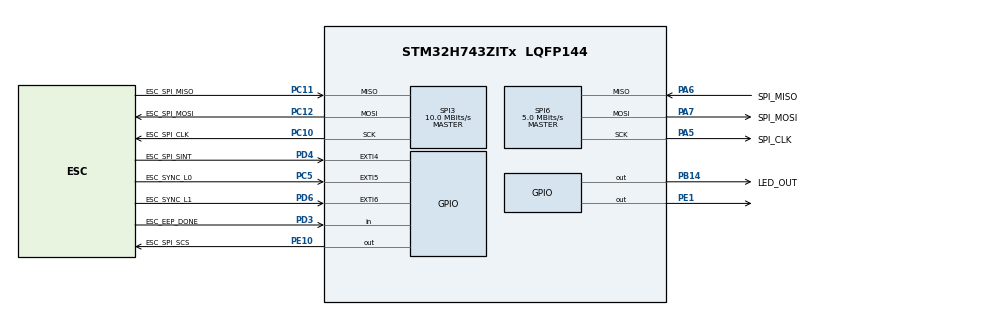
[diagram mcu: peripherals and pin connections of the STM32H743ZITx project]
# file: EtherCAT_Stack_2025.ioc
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CORTEX_M7.default_mode_Activation=1
Mcu.Family=STM32H7
Mcu.Name=STM32H743ZITx
Mcu.Package=LQFP144
NVIC.EXTI9_5_IRQn=true\:0\:0\:false\:false\:true\:true\:true\:true
NVIC.PriorityGroup=NVIC_PRIORITYGROUP_4
NVIC.SPI6_IRQn=true\:0\:0\:false\:false\:true\:true\:true\:true
NVIC.TIM7_IRQn=true\:0\:0\:false\:false\:true\:true\:true\:true
PA5.GPIO_Label=SPI_CLK
PA5.GPIO_Speed=GPIO_SPEED_FREQ_HIGH
PA5.Mode=Full_Duplex_Master
PA5.Signal=SPI6_SCK
PA6.GPIO_Label=SPI_MISO
PA6.GPIO_Speed=GPIO_SPEED_FREQ_VERY_HIGH
PA6.Mode=Full_Duplex_Master
PA6.Signal=SPI6_MISO
PA7.GPIO_Label=SPI_MOSI
PA7.GPIO_Speed=GPIO_SPEED_FREQ_HIGH
PA7.Mode=Full_Duplex_Master
PA7.Signal=SPI6_MOSI
PB14.GPIO_Label=LED_OUT
PB14.Signal=GPIO_Output
PC10.GPIO_Label=ESC_SPI_CLK
PC10.GPIO_PuPd=GPIO_PULLUP
PC10.GPIO_Speed=GPIO_SPEED_FREQ_HIGH
PC10.Mode=Full_Duplex_Master
PC10.Signal=SPI3_SCK
PC11.GPIO_Label=ESC_SPI_MISO
PC11.GPIO_Speed=GPIO_SPEED_FREQ_HIGH
PC11.Mode=Full_Duplex_Master
PC11.Signal=SPI3_MISO
PC12.GPIO_Label=ESC_SPI_MOSI
PC12.GPIO_PuPd=GPIO_PULLUP
PC12.GPIO_Speed=GPIO_SPEED_FREQ_HIGH
PC12.Mode=Full_Duplex_Master
PC12.Signal=SPI3_MOSI
PC5.GPIO_Label=ESC_SYNC_L0
PC5.GPIO_ModeDefaultEXTI=GPIO_MODE_IT_FALLING
PC5.GPIO_PuPd=GPIO_PULLUP
PC5.Signal=GPXTI5
PD3.GPIO_Label=ESC_EEP_DONE
PD3.GPIO_PuPd=GPIO_PULLDOWN
PD3.Signal=GPIO_Input
PD4.GPIO_Label=ESC_SPI_SINT
PD4.GPIO_ModeDefaultEXTI=GPIO_MODE_IT_FALLING
PD4.GPIO_PuPd=GPIO_PULLUP
PD4.Signal=GPXTI4
PD6.GPIO_Label=ESC_SYNC_L1
PD6.GPIO_ModeDefaultEXTI=GPIO_MODE_IT_FALLING
PD6.Signal=GPXTI6
PE1.Signal=GPIO_Output
PE10.GPIO_Label=ESC_SPI_SCS
PE10.GPIO_PuPd=GPIO_PULLUP
PE10.GPIO_Speed=GPIO_SPEED_FREQ_HIGH
PE10.PinState=GPIO_PIN_SET
PE10.Signal=GPIO_Output
ProjectManager.HeapSize=0x200
ProjectManager.StackSize=0x400
ProjectManager.TargetToolchain=STM32CubeIDE
RCC.ADCFreq_Value=129000000
RCC.APB1Freq_Value=80000000
RCC.APB2Freq_Value=80000000
RCC.APB3Freq_Value=80000000
RCC.APB4Freq_Value=40000000
RCC.CortexFreq_Value=80000000
RCC.D3PPRE=RCC_APB4_DIV2
RCC.DIVM1=4
RCC.DIVN1=10
RCC.HCLKFreq_Value=80000000
RCC.PLL2FRACN=0
RCC.PLL3FRACN=0
RCC.PLLFRACN=0
RCC.SYSCLKFreq_VALUE=80000000
RCC.SYSCLKSource=RCC_SYSCLKSOURCE_PLLCLK
RCC.USBFreq_Value=80000000
SPI3.BaudRatePrescaler=SPI_BAUDRATEPRESCALER_8
SPI3.CLKPhase=SPI_PHASE_2EDGE
SPI3.CLKPolarity=SPI_POLARITY_HIGH
SPI3.CalculateBaudRate=10.0 MBits/s
SPI3.DataSize=SPI_DATASIZE_8BIT
SPI3.Direction=SPI_DIRECTION_2LINES
SPI3.FifoThreshold=SPI_FIFO_THRESHOLD_04DATA
SPI3.Mode=SPI_MODE_MASTER
SPI3.VirtualType=VM_MASTER
SPI6.BaudRatePrescaler=SPI_BAUDRATEPRESCALER_8
SPI6.CLKPhase=SPI_PHASE_2EDGE
SPI6.CalculateBaudRate=5.0 MBits/s
SPI6.DataSize=SPI_DATASIZE_8BIT
SPI6.Direction=SPI_DIRECTION_2LINES
SPI6.Mode=SPI_MODE_MASTER
SPI6.VirtualType=VM_MASTER
TIM6.Period=999
TIM6.Prescaler=119
TIM7.Period=9999
TIM7.Prescaler=239
VP_MEMORYMAP_VS_MEMORYMAP.Mode=CurAppReg
VP_TIM6_VS_ClockSourceINT.Mode=Enable_Timer
VP_TIM7_VS_ClockSourceINT.Mode=Enable_Timer
board=custom

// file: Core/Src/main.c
/* USER CODE BEGIN Header */
/**
  ******************************************************************************
  * @file           : main.c
  * @brief          : Main program body
  ******************************************************************************
  * @attention
  *
  * Copyright (c) 2025 STMicroelectronics.
  * All rights reserved.
  *
  * This software is licensed under terms that can be found in the LICENSE file
  * in the root directory of this software component.
  * If no LICENSE file comes with this software, it is provided AS-IS.
  *
  ******************************************************************************
  */
/* USER CODE END Header */
#include "main.h"
#include "spi.h"
#include "tim.h"
#include "gpio.h"

void SystemClock_Config(void);
static void MPU_Config(void);

int main(void)
{

  /* MPU Configuration--------------------------------------------------------*/
  MPU_Config();

  /* MCU Configuration--------------------------------------------------------*/

  /* Reset of all peripherals, Initializes the Flash interface and the Systick. */
  HAL_Init();

  /* Configure the system clock */
  SystemClock_Config();

  /* Initialize all configured peripherals */
  MX_GPIO_Init();
  MX_SPI3_Init();
  MX_TIM6_Init();
  MX_TIM7_Init();
  MX_SPI6_Init();

  /* Infinite loop */
  while (1)
  {

    /* USER CODE BEGIN 3 */
	  main_initial();
	  //HAL_GPIO_WritePin(GPIOB, GPIO_PIN_14, 1);
  }
  /* USER CODE END 3 */
}

void SystemClock_Config(void)
{
  RCC_OscInitTypeDef RCC_OscInitStruct = {0};
  RCC_ClkInitTypeDef RCC_ClkInitStruct = {0};

  /** Supply configuration update enable
  */
  HAL_PWREx_ConfigSupply(PWR_LDO_SUPPLY);

  /** Configure the main internal regulator output voltage
  */
  __HAL_PWR_VOLTAGESCALING_CONFIG(PWR_REGULATOR_VOLTAGE_SCALE3);

  while(!__HAL_PWR_GET_FLAG(PWR_FLAG_VOSRDY)) {}

  /** Initializes the RCC Oscillators according to the specified parameters
  * in the RCC_OscInitTypeDef structure.
  */
  RCC_OscInitStruct.OscillatorType = RCC_OSCILLATORTYPE_HSI;
  RCC_OscInitStruct.HSIState = RCC_HSI_DIV1;
  RCC_OscInitStruct.HSICalibrationValue = RCC_HSICALIBRATION_DEFAULT;
  RCC_OscInitStruct.PLL.PLLState = RCC_PLL_ON;
  RCC_OscInitStruct.PLL.PLLSource = RCC_PLLSOURCE_HSI;
  RCC_OscInitStruct.PLL.PLLM = 4;
  RCC_OscInitStruct.PLL.PLLN = 10;
  RCC_OscInitStruct.PLL.PLLP = 2;
  RCC_OscInitStruct.PLL.PLLQ = 2;
  RCC_OscInitStruct.PLL.PLLR = 2;
  RCC_OscInitStruct.PLL.PLLRGE = RCC_PLL1VCIRANGE_3;
  RCC_OscInitStruct.PLL.PLLVCOSEL = RCC_PLL1VCOMEDIUM;
  RCC_OscInitStruct.PLL.PLLFRACN = 0;
  if (HAL_RCC_OscConfig(&RCC_OscInitStruct) != HAL_OK)
  {
    Error_Handler();
  }

  /** Initializes the CPU, AHB and APB buses clocks
  */
  RCC_ClkInitStruct.ClockType = RCC_CLOCKTYPE_HCLK|RCC_CLOCKTYPE_SYSCLK
                              |RCC_CLOCKTYPE_PCLK1|RCC_CLOCKTYPE_PCLK2
                              |RCC_CLOCKTYPE_D3PCLK1|RCC_CLOCKTYPE_D1PCLK1;
  RCC_ClkInitStruct.SYSCLKSource = RCC_SYSCLKSOURCE_PLLCLK;
  RCC_ClkInitStruct.SYSCLKDivider = RCC_SYSCLK_DIV1;
  RCC_ClkInitStruct.AHBCLKDivider = RCC_HCLK_DIV1;
  RCC_ClkInitStruct.APB3CLKDivider = RCC_APB3_DIV1;
  RCC_ClkInitStruct.APB1CLKDivider = RCC_APB1_DIV1;
  RCC_ClkInitStruct.APB2CLKDivider = RCC_APB2_DIV1;
  RCC_ClkInitStruct.APB4CLKDivider = RCC_APB4_DIV2;

  if (HAL_RCC_ClockConfig(&RCC_ClkInitStruct, FLASH_LATENCY_1) != HAL_OK)
  {
    Error_Handler();
  }
}

 /* MPU Configuration */

void MPU_Config(void)
{
  MPU_Region_InitTypeDef MPU_InitStruct = {0};

  /* Disables the MPU */
  HAL_MPU_Disable();

  /** Initializes and configures the Region and the memory to be protected
  */
  MPU_InitStruct.Enable = MPU_REGION_ENABLE;
  MPU_InitStruct.Number = MPU_REGION_NUMBER0;
  MPU_InitStruct.BaseAddress = 0x0;
  MPU_InitStruct.Size = MPU_REGION_SIZE_4GB;
  MPU_InitStruct.SubRegionDisable = 0x87;
  MPU_InitStruct.TypeExtField = MPU_TEX_LEVEL0;
  MPU_InitStruct.AccessPermission = MPU_REGION_NO_ACCESS;
  MPU_InitStruct.DisableExec = MPU_INSTRUCTION_ACCESS_DISABLE;
  MPU_InitStruct.IsShareable = MPU_ACCESS_SHAREABLE;
  MPU_InitStruct.IsCacheable = MPU_ACCESS_NOT_CACHEABLE;
  MPU_InitStruct.IsBufferable = MPU_ACCESS_NOT_BUFFERABLE;

  HAL_MPU_ConfigRegion(&MPU_InitStruct);
  /* Enables the MPU */
  HAL_MPU_Enable(MPU_PRIVILEGED_DEFAULT);

}

void Error_Handler(void)
{
  __disable_irq();
  while (1)
  {
  }
}
